AUTOSAR XML (schema 4-0-3)
standard types defined: Boolean, UInt16, UInt8
package /AUTOSAR_Platform/DataConstrs
  range DC_Boolean: raw 0..1
  range DC_UInt16: raw 0..65535
package /PATAC/MSM/ComponentTypes
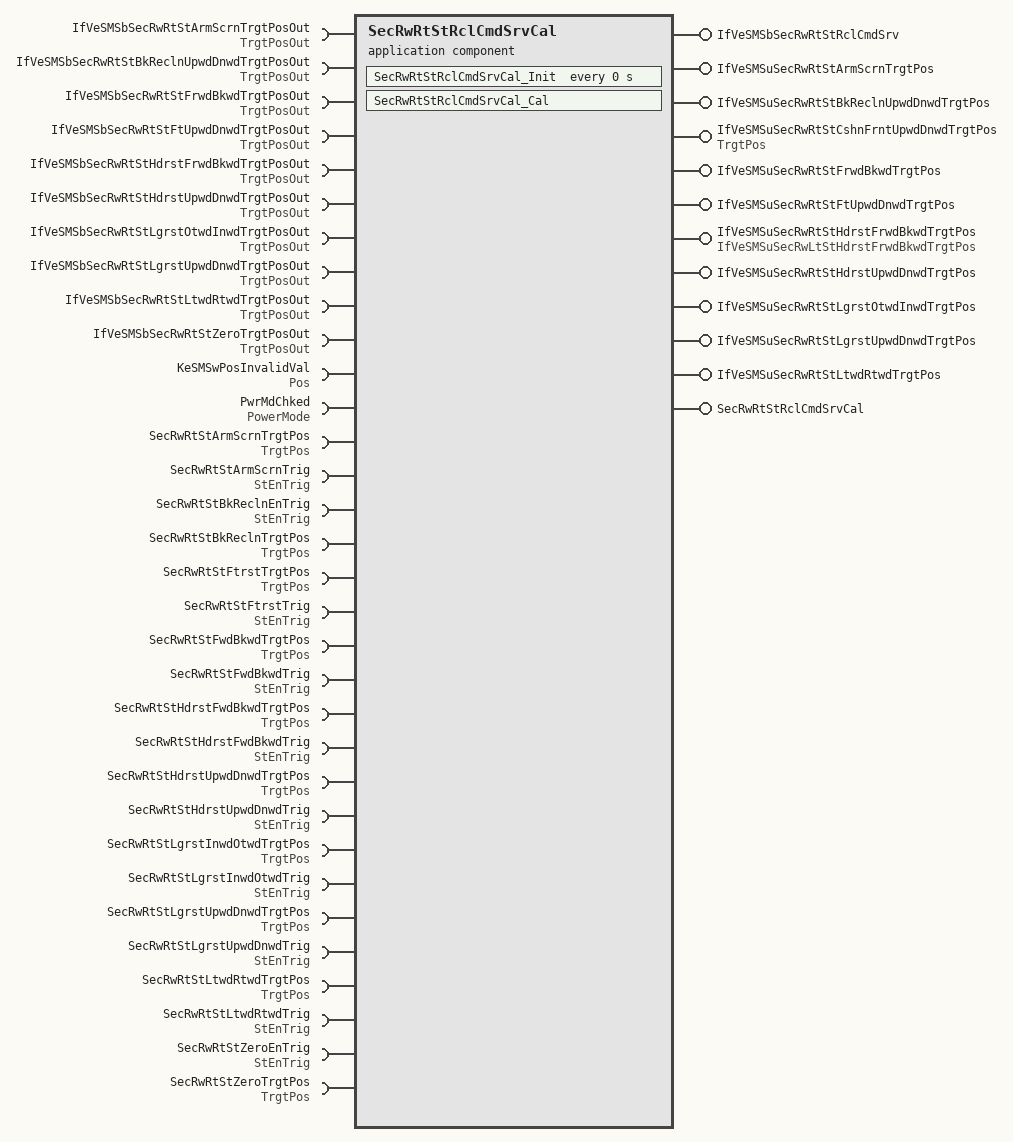
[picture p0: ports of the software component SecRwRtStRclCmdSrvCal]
  application sw component type SecRwRtStRclCmdSrvCal
    12 x provide port:
      IfVeSMSbSecRwRtStRclCmdSrv: nonqueued-sender-com-spec{data-element=IfVeSMSbSecRwRtStRclCmdSrv/Val, init-value=0}, provided-interface=IfVeSMSbSecRwRtStRclCmdSrv
      IfVeSMSuSecRwRtStArmScrnTrgtPos: nonqueued-sender-com-spec{data-element=IfVeSMSuSecRwRtStArmScrnTrgtPos/Val, init-value=4095}, provided-interface=IfVeSMSuSecRwRtStArmScrnTrgtPos
      IfVeSMSuSecRwRtStBkReclnUpwdDnwdTrgtPos: nonqueued-sender-com-spec{data-element=IfVeSMSuSecRwRtStBkReclnUpwdDnwdTrgtPos/Val, init-value=4095}, provided-interface=IfVeSMSuSecRwRtStBkReclnUpwdDnwdTrgtPos
      IfVeSMSuSecRwRtStCshnFrntUpwdDnwdTrgtPos: nonqueued-sender-com-spec{data-element=TrgtPos/Val, init-value=4095}, provided-interface=TrgtPos
      IfVeSMSuSecRwRtStFrwdBkwdTrgtPos: nonqueued-sender-com-spec{data-element=IfVeSMSuSecRwRtStFrwdBkwdTrgtPos/Val, init-value=4095}, provided-interface=IfVeSMSuSecRwRtStFrwdBkwdTrgtPos
      IfVeSMSuSecRwRtStFtUpwdDnwdTrgtPos: nonqueued-sender-com-spec{data-element=IfVeSMSuSecRwRtStFtUpwdDnwdTrgtPos/Val, init-value=4095}, provided-interface=IfVeSMSuSecRwRtStFtUpwdDnwdTrgtPos
      IfVeSMSuSecRwRtStHdrstFrwdBkwdTrgtPos: nonqueued-sender-com-spec{data-element=IfVeSMSuSecRwLtStHdrstFrwdBkwdTrgtPos/Val, init-value=4095}, provided-interface=IfVeSMSuSecRwLtStHdrstFrwdBkwdTrgtPos
      IfVeSMSuSecRwRtStHdrstUpwdDnwdTrgtPos: nonqueued-sender-com-spec{data-element=IfVeSMSuSecRwRtStHdrstUpwdDnwdTrgtPos/Val, init-value=4095}, provided-interface=IfVeSMSuSecRwRtStHdrstUpwdDnwdTrgtPos
      IfVeSMSuSecRwRtStLgrstOtwdInwdTrgtPos: nonqueued-sender-com-spec{data-element=IfVeSMSuSecRwRtStLgrstOtwdInwdTrgtPos/Val, init-value=4095}, provided-interface=IfVeSMSuSecRwRtStLgrstOtwdInwdTrgtPos
      IfVeSMSuSecRwRtStLgrstUpwdDnwdTrgtPos: nonqueued-sender-com-spec{data-element=IfVeSMSuSecRwRtStLgrstUpwdDnwdTrgtPos/Val, init-value=4095}, provided-interface=IfVeSMSuSecRwRtStLgrstUpwdDnwdTrgtPos
      IfVeSMSuSecRwRtStLtwdRtwdTrgtPos: nonqueued-sender-com-spec{data-element=IfVeSMSuSecRwRtStLtwdRtwdTrgtPos/Val, init-value=4095}, provided-interface=IfVeSMSuSecRwRtStLtwdRtwdTrgtPos
      SecRwRtStRclCmdSrvCal: server-com-spec{operation=Cal, queue-length=1}, provided-interface=SecRwRtStRclCmdSrvCal
    32 x require port:
      IfVeSMSbSecRwRtStArmScrnTrgtPosOut: nonqueued-receiver-com-spec{data-element=TrgtPosOut/Val, filter=data-filter-type=ALWAYS, init-value=0}, required-interface=TrgtPosOut
      IfVeSMSbSecRwRtStBkReclnUpwdDnwdTrgtPosOut: nonqueued-receiver-com-spec{data-element=TrgtPosOut/Val, filter=data-filter-type=ALWAYS, init-value=0}, required-interface=TrgtPosOut
      IfVeSMSbSecRwRtStFrwdBkwdTrgtPosOut: nonqueued-receiver-com-spec{data-element=TrgtPosOut/Val, filter=data-filter-type=ALWAYS, init-value=0}, required-interface=TrgtPosOut
      IfVeSMSbSecRwRtStFtUpwdDnwdTrgtPosOut: nonqueued-receiver-com-spec{data-element=TrgtPosOut/Val, filter=data-filter-type=ALWAYS, init-value=0}, required-interface=TrgtPosOut
      IfVeSMSbSecRwRtStHdrstFrwdBkwdTrgtPosOut: nonqueued-receiver-com-spec{data-element=TrgtPosOut/Val, filter=data-filter-type=ALWAYS, init-value=0}, required-interface=TrgtPosOut
      IfVeSMSbSecRwRtStHdrstUpwdDnwdTrgtPosOut: nonqueued-receiver-com-spec{data-element=TrgtPosOut/Val, filter=data-filter-type=ALWAYS, init-value=0}, required-interface=TrgtPosOut
      IfVeSMSbSecRwRtStLgrstOtwdInwdTrgtPosOut: nonqueued-receiver-com-spec{data-element=TrgtPosOut/Val, filter=data-filter-type=ALWAYS, init-value=0}, required-interface=TrgtPosOut
      IfVeSMSbSecRwRtStLgrstUpwdDnwdTrgtPosOut: nonqueued-receiver-com-spec{data-element=TrgtPosOut/Val, filter=data-filter-type=ALWAYS, init-value=0}, required-interface=TrgtPosOut
      IfVeSMSbSecRwRtStLtwdRtwdTrgtPosOut: nonqueued-receiver-com-spec{data-element=TrgtPosOut/Val, filter=data-filter-type=ALWAYS, init-value=0}, required-interface=TrgtPosOut
      IfVeSMSbSecRwRtStZeroTrgtPosOut: nonqueued-receiver-com-spec{data-element=TrgtPosOut/Val, filter=data-filter-type=ALWAYS, init-value=0}, required-interface=TrgtPosOut
      KeSMSwPosInvalidVal: parameter-require-com-spec{init-value=4095, parameter=Val}, required-interface=Pos
      PwrMdChked: nonqueued-receiver-com-spec{data-element=PowerMode/Val, filter=data-filter-type=ALWAYS, init-value=0}, required-interface=PowerMode
      SecRwRtStArmScrnTrgtPos: nonqueued-receiver-com-spec{data-element=TrgtPos/Val, filter=data-filter-type=ALWAYS, init-value=4095}, required-interface=TrgtPos
      SecRwRtStArmScrnTrig: nonqueued-receiver-com-spec{data-element=StEnTrig/Val, filter=data-filter-type=ALWAYS, init-value=0}, required-interface=StEnTrig
      SecRwRtStBkReclnEnTrig: nonqueued-receiver-com-spec{data-element=StEnTrig/Val, filter=data-filter-type=ALWAYS, init-value=0}, required-interface=StEnTrig
      SecRwRtStBkReclnTrgtPos: nonqueued-receiver-com-spec{data-element=TrgtPos/Val, filter=data-filter-type=ALWAYS, init-value=4095}, required-interface=TrgtPos
      SecRwRtStFtrstTrgtPos: nonqueued-receiver-com-spec{data-element=TrgtPos/Val, filter=data-filter-type=ALWAYS, init-value=4095}, required-interface=TrgtPos
      SecRwRtStFtrstTrig: nonqueued-receiver-com-spec{data-element=StEnTrig/Val, filter=data-filter-type=ALWAYS, init-value=0}, required-interface=StEnTrig
      SecRwRtStFwdBkwdTrgtPos: nonqueued-receiver-com-spec{data-element=TrgtPos/Val, filter=data-filter-type=ALWAYS, init-value=4095}, required-interface=TrgtPos
      SecRwRtStFwdBkwdTrig: nonqueued-receiver-com-spec{data-element=StEnTrig/Val, filter=data-filter-type=ALWAYS, init-value=0}, required-interface=StEnTrig
      SecRwRtStHdrstFwdBkwdTrgtPos: nonqueued-receiver-com-spec{data-element=TrgtPos/Val, filter=data-filter-type=ALWAYS, init-value=4095}, required-interface=TrgtPos
      SecRwRtStHdrstFwdBkwdTrig: nonqueued-receiver-com-spec{data-element=StEnTrig/Val, filter=data-filter-type=ALWAYS, init-value=0}, required-interface=StEnTrig
      SecRwRtStHdrstUpwdDnwdTrgtPos: nonqueued-receiver-com-spec{data-element=TrgtPos/Val, filter=data-filter-type=ALWAYS, init-value=4095}, required-interface=TrgtPos
      SecRwRtStHdrstUpwdDnwdTrig: nonqueued-receiver-com-spec{data-element=StEnTrig/Val, filter=data-filter-type=ALWAYS, init-value=0}, required-interface=StEnTrig
      SecRwRtStLgrstInwdOtwdTrgtPos: nonqueued-receiver-com-spec{data-element=TrgtPos/Val, filter=data-filter-type=ALWAYS, init-value=4095}, required-interface=TrgtPos
      SecRwRtStLgrstInwdOtwdTrig: nonqueued-receiver-com-spec{data-element=StEnTrig/Val, filter=data-filter-type=ALWAYS, init-value=0}, required-interface=StEnTrig
      SecRwRtStLgrstUpwdDnwdTrgtPos: nonqueued-receiver-com-spec{data-element=TrgtPos/Val, filter=data-filter-type=ALWAYS, init-value=4095}, required-interface=TrgtPos
      SecRwRtStLgrstUpwdDnwdTrig: nonqueued-receiver-com-spec{data-element=StEnTrig/Val, filter=data-filter-type=ALWAYS, init-value=0}, required-interface=StEnTrig
      SecRwRtStLtwdRtwdTrgtPos: nonqueued-receiver-com-spec{data-element=TrgtPos/Val, filter=data-filter-type=ALWAYS, init-value=4095}, required-interface=TrgtPos
      SecRwRtStLtwdRtwdTrig: nonqueued-receiver-com-spec{data-element=StEnTrig/Val, filter=data-filter-type=ALWAYS, init-value=0}, required-interface=StEnTrig
      SecRwRtStZeroEnTrig: nonqueued-receiver-com-spec{data-element=StEnTrig/Val, filter=data-filter-type=ALWAYS, init-value=0}, required-interface=StEnTrig
      SecRwRtStZeroTrgtPos: nonqueued-receiver-com-spec{data-element=TrgtPos/Val, filter=data-filter-type=ALWAYS, init-value=4095}, required-interface=TrgtPos
    behavior SecRwRtStRclCmdSrvCal_InternalBehavior
      operation invoked event OIT_SecRwRtStRclCmdSrvCal_Cal_SecRwRtStRclCmdSrvCal_Cal: start-on-event=SecRwRtStRclCmdSrvCal_Cal, operation=SecRwRtStRclCmdSrvCal.Cal
      timing event SecRwRtStRclCmdSrvCal_InitEvent: start-on-event=SecRwRtStRclCmdSrvCal_Init, period=0
      runnable SecRwRtStRclCmdSrvCal_Cal
        data-receive-point-by-arguments:
          31 x access:
            REC_IfVeSMSbSecRwRtStArmScrnTrgtPosOut_Val: accessed-variable=IfVeSMSbSecRwRtStArmScrnTrgtPosOut.Val
            REC_IfVeSMSbSecRwRtStBkReclnUpwdDnwdTrgtPosOut_Val: accessed-variable=IfVeSMSbSecRwRtStBkReclnUpwdDnwdTrgtPosOut.Val
            REC_IfVeSMSbSecRwRtStFrwdBkwdTrgtPosOut_Val: accessed-variable=IfVeSMSbSecRwRtStFrwdBkwdTrgtPosOut.Val
            REC_IfVeSMSbSecRwRtStFtUpwdDnwdTrgtPosOut_Val: accessed-variable=IfVeSMSbSecRwRtStFtUpwdDnwdTrgtPosOut.Val
            REC_IfVeSMSbSecRwRtStHdrstFrwdBkwdTrgtPosOut_Val: accessed-variable=IfVeSMSbSecRwRtStHdrstFrwdBkwdTrgtPosOut.Val
            REC_IfVeSMSbSecRwRtStHdrstUpwdDnwdTrgtPosOut_Val: accessed-variable=IfVeSMSbSecRwRtStHdrstUpwdDnwdTrgtPosOut.Val
            REC_IfVeSMSbSecRwRtStLgrstOtwdInwdTrgtPosOut_Val: accessed-variable=IfVeSMSbSecRwRtStLgrstOtwdInwdTrgtPosOut.Val
            REC_IfVeSMSbSecRwRtStLgrstUpwdDnwdTrgtPosOut_Val: accessed-variable=IfVeSMSbSecRwRtStLgrstUpwdDnwdTrgtPosOut.Val
            REC_IfVeSMSbSecRwRtStLtwdRtwdTrgtPosOut_Val: accessed-variable=IfVeSMSbSecRwRtStLtwdRtwdTrgtPosOut.Val
            REC_IfVeSMSbSecRwRtStZeroTrgtPosOut_Val: accessed-variable=IfVeSMSbSecRwRtStZeroTrgtPosOut.Val
            REC_PwrMdChked_Val: accessed-variable=PwrMdChked.Val
            REC_SecRwRtStArmScrnTrgtPos_Val: accessed-variable=SecRwRtStArmScrnTrgtPos.Val
            REC_SecRwRtStArmScrnTrig_Val: accessed-variable=SecRwRtStArmScrnTrig.Val
            REC_SecRwRtStBkReclnEnTrig_Val: accessed-variable=SecRwRtStBkReclnEnTrig.Val
            REC_SecRwRtStBkReclnTrgtPos_Val: accessed-variable=SecRwRtStBkReclnTrgtPos.Val
            REC_SecRwRtStFtrstTrgtPos_Val: accessed-variable=SecRwRtStFtrstTrgtPos.Val
            REC_SecRwRtStFtrstTrig_Val: accessed-variable=SecRwRtStFtrstTrig.Val
            REC_SecRwRtStFwdBkwdTrgtPos_Val: accessed-variable=SecRwRtStFwdBkwdTrgtPos.Val
            REC_SecRwRtStFwdBkwdTrig_Val: accessed-variable=SecRwRtStFwdBkwdTrig.Val
            REC_SecRwRtStHdrstFwdBkwdTrgtPos_Val: accessed-variable=SecRwRtStHdrstFwdBkwdTrgtPos.Val
            REC_SecRwRtStHdrstFwdBkwdTrig_Val: accessed-variable=SecRwRtStHdrstFwdBkwdTrig.Val
            REC_SecRwRtStHdrstUpwdDnwdTrgtPos_Val: accessed-variable=SecRwRtStHdrstUpwdDnwdTrgtPos.Val
            REC_SecRwRtStHdrstUpwdDnwdTrig_Val: accessed-variable=SecRwRtStHdrstUpwdDnwdTrig.Val
            REC_SecRwRtStLgrstInwdOtwdTrgtPos_Val: accessed-variable=SecRwRtStLgrstInwdOtwdTrgtPos.Val
            REC_SecRwRtStLgrstInwdOtwdTrig_Val: accessed-variable=SecRwRtStLgrstInwdOtwdTrig.Val
            REC_SecRwRtStLgrstUpwdDnwdTrgtPos_Val: accessed-variable=SecRwRtStLgrstUpwdDnwdTrgtPos.Val
            REC_SecRwRtStLgrstUpwdDnwdTrig_Val: accessed-variable=SecRwRtStLgrstUpwdDnwdTrig.Val
            REC_SecRwRtStLtwdRtwdTrgtPos_Val: accessed-variable=SecRwRtStLtwdRtwdTrgtPos.Val
            REC_SecRwRtStLtwdRtwdTrig_Val: accessed-variable=SecRwRtStLtwdRtwdTrig.Val
            REC_SecRwRtStZeroEnTrig_Val: accessed-variable=SecRwRtStZeroEnTrig.Val
            REC_SecRwRtStZeroTrgtPos_Val: accessed-variable=SecRwRtStZeroTrgtPos.Val
        data-send-points:
          11 x access:
            SEND_IfVeSMSbSecRwRtStRclCmdSrv_Val: accessed-variable=IfVeSMSbSecRwRtStRclCmdSrv.Val
            SEND_IfVeSMSuSecRwRtStArmScrnTrgtPos_Val: accessed-variable=IfVeSMSuSecRwRtStArmScrnTrgtPos.Val
            SEND_IfVeSMSuSecRwRtStBkReclnUpwdDnwdTrgtPos_Val: accessed-variable=IfVeSMSuSecRwRtStBkReclnUpwdDnwdTrgtPos.Val
            SEND_IfVeSMSuSecRwRtStCshnFrntUpwdDnwdTrgtPos_Val: accessed-variable=IfVeSMSuSecRwRtStCshnFrntUpwdDnwdTrgtPos.Val
            SEND_IfVeSMSuSecRwRtStFrwdBkwdTrgtPos_Val: accessed-variable=IfVeSMSuSecRwRtStFrwdBkwdTrgtPos.Val
            SEND_IfVeSMSuSecRwRtStFtUpwdDnwdTrgtPos_Val: accessed-variable=IfVeSMSuSecRwRtStFtUpwdDnwdTrgtPos.Val
            SEND_IfVeSMSuSecRwRtStHdrstFrwdBkwdTrgtPos_Val: accessed-variable=IfVeSMSuSecRwRtStHdrstFrwdBkwdTrgtPos.Val
            SEND_IfVeSMSuSecRwRtStHdrstUpwdDnwdTrgtPos_Val: accessed-variable=IfVeSMSuSecRwRtStHdrstUpwdDnwdTrgtPos.Val
            SEND_IfVeSMSuSecRwRtStLgrstOtwdInwdTrgtPos_Val: accessed-variable=IfVeSMSuSecRwRtStLgrstOtwdInwdTrgtPos.Val
            SEND_IfVeSMSuSecRwRtStLgrstUpwdDnwdTrgtPos_Val: accessed-variable=IfVeSMSuSecRwRtStLgrstUpwdDnwdTrgtPos.Val
            SEND_IfVeSMSuSecRwRtStLtwdRtwdTrgtPos_Val: accessed-variable=IfVeSMSuSecRwRtStLtwdRtwdTrgtPos.Val
        parameter access PA_KeSMSwPosInvalidVal_Val: accessed-parameter=KeSMSwPosInvalidVal.Val
      runnable SecRwRtStRclCmdSrvCal_Init
        parameter access PA_KeSMSwPosInvalidVal_Val: accessed-parameter=KeSMSwPosInvalidVal.Val
  swc implementation SecRwRtStRclCmdSrvCal_Implementation: behavior=SecRwRtStRclCmdSrvCal_InternalBehavior
    code-descriptors:
      code Default: artifact-descriptors=autosar-engineering-object={short-label=Default, category=SWSRC}
package /PATAC/MSM/ModeAdjust/CalPortInterface
  parameter interface Pos
    parameter data prototype Val: sw-calibration-access=READ-WRITE, type=UInt16
package /PATAC/MSM/ModeAdjust/DataType
  impl type PowerMode1: category=VALUE, base-type=UInt8, sw-calibration-access=READ-ONLY, compu {0=PowerMode_Off, 1=PowerMode_Acc, 2=PowerMode_Run, 3=PowerMode_Crank, 4=PowerMode_Invalid}, type-emitter=RTE
package /PATAC/MSM/ModeAdjust/PortInterface
  client server interface SecRwRtStRclCmdSrvCal
    operation Cal
  sender receiver interface PowerMode: invalidation-policy{data-element=PowerMode/Val, handle-invalid=DONT-INVALIDATE}
    data Val: type=PowerMode1
  sender receiver interface StEnTrig: invalidation-policy{data-element=StEnTrig/Val, handle-invalid=DONT-INVALIDATE}
    data Val: type=Boolean
  sender receiver interface TrgtPosOut: invalidation-policy{data-element=TrgtPosOut/Val, handle-invalid=DONT-INVALIDATE}
    data Val: type=Boolean
package /PATAC/MSM/PortInterfaces
  11 x sender receiver interface:
    IfVeSMSbSecRwRtStRclCmdSrv: invalidation-policy{data-element=IfVeSMSbSecRwRtStRclCmdSrv/Val, handle-invalid=DONT-INVALIDATE}
      data Val: type=Boolean
    IfVeSMSuSecRwLtStHdrstFrwdBkwdTrgtPos: invalidation-policy{data-element=IfVeSMSuSecRwLtStHdrstFrwdBkwdTrgtPos/Val, handle-invalid=DONT-INVALIDATE}
      data Val: type=UInt16
    IfVeSMSuSecRwRtStArmScrnTrgtPos: invalidation-policy{data-element=IfVeSMSuSecRwRtStArmScrnTrgtPos/Val, handle-invalid=DONT-INVALIDATE}
      data Val: type=UInt16
    IfVeSMSuSecRwRtStBkReclnUpwdDnwdTrgtPos: invalidation-policy{data-element=IfVeSMSuSecRwRtStBkReclnUpwdDnwdTrgtPos/Val, handle-invalid=DONT-INVALIDATE}
      data Val: type=UInt16
    IfVeSMSuSecRwRtStFrwdBkwdTrgtPos: invalidation-policy{data-element=IfVeSMSuSecRwRtStFrwdBkwdTrgtPos/Val, handle-invalid=DONT-INVALIDATE}
      data Val: type=UInt16
    IfVeSMSuSecRwRtStFtUpwdDnwdTrgtPos: invalidation-policy{data-element=IfVeSMSuSecRwRtStFtUpwdDnwdTrgtPos/Val, handle-invalid=DONT-INVALIDATE}
      data Val: type=UInt16
    IfVeSMSuSecRwRtStHdrstUpwdDnwdTrgtPos: invalidation-policy{data-element=IfVeSMSuSecRwRtStHdrstUpwdDnwdTrgtPos/Val, handle-invalid=DONT-INVALIDATE}
      data Val: type=UInt16
    IfVeSMSuSecRwRtStLgrstOtwdInwdTrgtPos: invalidation-policy{data-element=IfVeSMSuSecRwRtStLgrstOtwdInwdTrgtPos/Val, handle-invalid=DONT-INVALIDATE}
      data Val: type=UInt16
    IfVeSMSuSecRwRtStLgrstUpwdDnwdTrgtPos: invalidation-policy{data-element=IfVeSMSuSecRwRtStLgrstUpwdDnwdTrgtPos/Val, handle-invalid=DONT-INVALIDATE}
      data Val: type=UInt16
    IfVeSMSuSecRwRtStLtwdRtwdTrgtPos: invalidation-policy{data-element=IfVeSMSuSecRwRtStLtwdRtwdTrgtPos/Val, handle-invalid=DONT-INVALIDATE}
      data Val: type=UInt16
    TrgtPos: invalidation-policy{data-element=TrgtPos/Val, handle-invalid=DONT-INVALIDATE}
      data Val: type=UInt16
